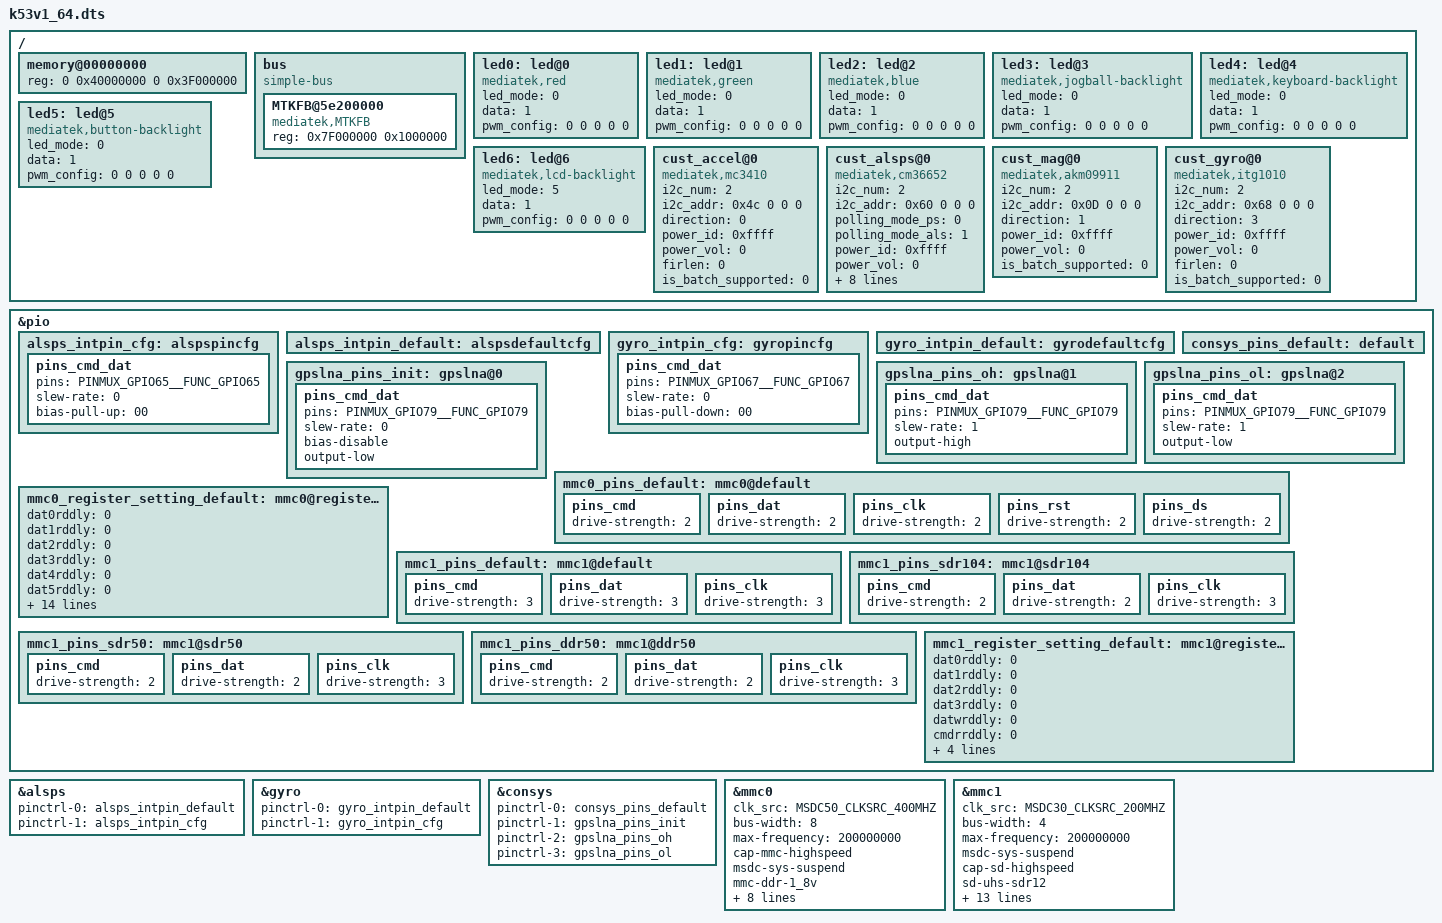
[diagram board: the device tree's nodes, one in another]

/dts-v1/;

#include "mt6753.dtsi"

/ {
	memory@00000000 {
		device_type = "memory";
		reg = <0 0x40000000 0 0x3F000000>;
	};

	bus {
		compatible = "simple-bus";
		#address-cells = <1>;
		#size-cells = <1>;
		ranges = <0 0 0 0xffffffff>;

		MTKFB@5e200000 {
			compatible = "mediatek,MTKFB";
			reg = <0x7F000000 0x1000000>;
		};
	};
	led0:led@0 {
		compatible = "mediatek,red";
		led_mode = <0>;
		data = <1>;
		pwm_config = <0 0 0 0 0>;
	};
	led1:led@1 {
		compatible = "mediatek,green";
		led_mode = <0>;
		data = <1>;
		pwm_config = <0 0 0 0 0>;
	};
	led2:led@2 {
		compatible = "mediatek,blue";
		led_mode = <0>;
		data = <1>;
		pwm_config = <0 0 0 0 0>;
	};
	led3:led@3 {
		compatible = "mediatek,jogball-backlight";
		led_mode = <0>;
		data = <1>;
		pwm_config = <0 0 0 0 0>;
	};
	led4:led@4 {
		compatible = "mediatek,keyboard-backlight";
		led_mode = <0>;
		data = <1>;
		pwm_config = <0 0 0 0 0>;
	};
	led5:led@5 {
		compatible = "mediatek,button-backlight";
		led_mode = <0>;
		data = <1>;
		pwm_config = <0 0 0 0 0>;
	};
	led6:led@6 {
		compatible = "mediatek,lcd-backlight";
		led_mode = <5>;
		data = <1>;
		pwm_config = <0 0 0 0 0>;
	};
 /* sensor standardization */
		cust_accel@0 {
		compatible = "mediatek,mc3410";
		i2c_num	= <2>;
		i2c_addr = <0x4c 0 0 0>;
		direction = <0>;
		power_id = <0xffff>;
		power_vol = <0>;
		firlen = <0>;
		is_batch_supported = <0>;
		};

		cust_alsps@0 {
		compatible = "mediatek,cm36652";
		i2c_num	= <2>;
		i2c_addr = <0x60 0 0 0>;
		polling_mode_ps = <0>;
		polling_mode_als = <1>;
		power_id = <0xffff>;
		power_vol = <0>;
		als_level = <0 213 711 1143 2630 6803 6909 10736 19968 24783 29231 42000 51141 51141 51141>;
		als_value = <0 135 303 501 1005 2005 3209 5002 8006 10010 12000 16010 20000 20000 20000 20000>;
		ps_threshold_high		=  <32>;
		ps_threshold_low		=  <22>;
		is_batch_supported_ps	= <0>;
		is_batch_supported_als	= <0>;
		};

		cust_mag@0 {
		compatible				= "mediatek,akm09911";
		i2c_num					= <2>;
		i2c_addr				= <0x0D 0 0 0>;
		direction				= <1>;
		power_id				= <0xffff>;
		power_vol				= <0>;
		is_batch_supported			= <0>;
		};

		cust_gyro@0 {
		compatible				= "mediatek,itg1010";
		i2c_num					= <2>;
		i2c_addr				= <0x68 0 0 0>;
		direction				= <3>;
		power_id				= <0xffff>;
		power_vol				= <0>;
		firlen					= <0>;
		is_batch_supported			= <0>;
		};
};
/* sensor gpio standization */
&pio {
	alsps_intpin_cfg: alspspincfg {

	    pins_cmd_dat {
			pins = <PINMUX_GPIO65__FUNC_GPIO65>;
			slew-rate = <0>;
			bias-pull-up = <00>;
		};
	};

	alsps_intpin_default: alspsdefaultcfg {

	};

	gyro_intpin_cfg: gyropincfg {

	    pins_cmd_dat {
			pins = <PINMUX_GPIO67__FUNC_GPIO67>;
			slew-rate = <0>;
			bias-pull-down = <00>;
		};
	};

	gyro_intpin_default: gyrodefaultcfg {

	};
};
&alsps {
	pinctrl-names = "pin_default", "pin_cfg";
	pinctrl-0 = <&alsps_intpin_default>;
	pinctrl-1 = <&alsps_intpin_cfg>;
	status = "okay";

};

&gyro {
	pinctrl-names = "pin_default", "pin_cfg";
	pinctrl-0 = <&gyro_intpin_default>;
	pinctrl-1 = <&gyro_intpin_cfg>;
	status = "okay";

};
/* sensor end */

/* CONSYS GPIO standardization */
&pio {
	consys_pins_default: default {

	};

	gpslna_pins_init: gpslna@0 {

	    pins_cmd_dat {
			pins = <PINMUX_GPIO79__FUNC_GPIO79>;
			slew-rate = <0>;
			bias-disable;
			output-low;
		};
	};

	gpslna_pins_oh: gpslna@1 {

	    pins_cmd_dat {
			pins = <PINMUX_GPIO79__FUNC_GPIO79>;
			slew-rate = <1>;
			output-high;
		};
	};

	gpslna_pins_ol: gpslna@2 {

	    pins_cmd_dat {
			pins = <PINMUX_GPIO79__FUNC_GPIO79>;
			slew-rate = <1>;
			output-low;
		};
	};

};

&consys {
	pinctrl-names = "default", "gps_lna_state_init", "gps_lna_state_oh", "gps_lna_state_ol";
	pinctrl-0 = <&consys_pins_default>;
	pinctrl-1 = <&gpslna_pins_init>;
	pinctrl-2 = <&gpslna_pins_oh>;
	pinctrl-3 = <&gpslna_pins_ol>;
	status = "okay";

};
/* CONSYS end */
/* mmc start */
&mmc0 {
		clk_src = /bits/ 8 <MSDC50_CLKSRC_400MHZ>;
		bus-width = <8>;
		max-frequency = <200000000>;
		cap-mmc-highspeed;
		msdc-sys-suspend;
		mmc-ddr-1_8v;
		mmc-hs200-1_8v;
		mmc-hs400-1_8v;
		non-removable;
		pinctl = <&mmc0_pins_default>;
		register_setting = <&mmc0_register_setting_default>;
		host_function = /bits/ 8 <MSDC_EMMC>;
		bootable;
		status = "okay";
};

&mmc1 {
		clk_src = /bits/ 8 <MSDC30_CLKSRC_200MHZ>;
		bus-width = <4>;
		max-frequency = <200000000>;
		msdc-sys-suspend;
		cap-sd-highspeed;
		sd-uhs-sdr12;
		sd-uhs-sdr25;
		sd-uhs-sdr50;
		sd-uhs-sdr104;
		sd-uhs-ddr50;
		pinctl = <&mmc1_pins_default>;
		pinctl_sdr104 = <&mmc1_pins_sdr104>;
		pinctl_sdr50 = <&mmc1_pins_sdr50>;
		pinctl_ddr50 = <&mmc1_pins_ddr50>;
		register_setting = <&mmc1_register_setting_default>;
		host_function = /bits/ 8 <MSDC_SD>;
		cd_level = /bits/ 8 <MSDC_CD_LOW>;
		cd-gpios = <&pio 5 0>;
		status = "okay";
};

&pio {
	mmc0_pins_default: mmc0@default {
			pins_cmd {
				drive-strength = /bits/ 8 <2>;
			};
			pins_dat {
				drive-strength = /bits/ 8 <2>;
			};
			pins_clk {
				drive-strength = /bits/ 8 <2>;
			};
			pins_rst {
				drive-strength = /bits/ 8 <2>;
			};
			pins_ds {
				drive-strength = /bits/ 8 <2>;
			};
	};

	mmc0_register_setting_default: mmc0@register_default {
		dat0rddly      = /bits/ 8 <0>;
		dat1rddly      = /bits/ 8 <0>;
		dat2rddly      = /bits/ 8 <0>;
		dat3rddly      = /bits/ 8 <0>;
		dat4rddly      = /bits/ 8 <0>;
		dat5rddly      = /bits/ 8 <0>;
		dat6rddly      = /bits/ 8 <0>;
		dat7rddly      = /bits/ 8 <0>;
		datwrddly      = /bits/ 8 <0>;
		cmdrrddly      = /bits/ 8 <0>;
		cmdrddly       = /bits/ 8 <0>;
		cmd_edge = /bits/ 8 <MSDC_SMPL_FALLING>;
		rdata_edge = /bits/ 8 <MSDC_SMPL_FALLING>;
		wdata_edge = /bits/ 8 <MSDC_SMPL_FALLING>;

		ett-hs200-cells = <12>;
		ett-hs200-default = <OFFSET_MSDC_PATCH_BIT0	MSDC_PB0_INT_DAT_LATCH_CK_SEL 0x0
			OFFSET_MSDC_PATCH_BIT0	MSDC_PB0_CKGEN_MSDC_DLY_SEL   0x0
			OFFSET_MSDC_PATCH_BIT1	MSDC_PB1_CMD_RSP_TA_CNTR      0x1
			OFFSET_MSDC_IOCON		MSDC_IOCON_RSPL               0x0
			OFFSET_MSDC_PAD_TUNE0	MSDC_PAD_TUNE0_CMDRDLY        0x7
			OFFSET_MSDC_PAD_TUNE0	MSDC_PAD_TUNE0_CMDRRDLY       0xb
			OFFSET_MSDC_PATCH_BIT1		MSDC_PB1_WRDAT_CRCS_TA_CNTR   0x1
			OFFSET_MSDC_PAD_TUNE0	MSDC_PAD_TUNE0_DATWRDLY       0xb
			OFFSET_MSDC_IOCON			MSDC_IOCON_W_D0SPL            0x0
			OFFSET_MSDC_DAT_RDDLY0		MSDC_DAT_RDDLY0_D0            0x7
			OFFSET_MSDC_PAD_TUNE0	MSDC_PAD_TUNE0_DATRRDLY       0x9
			OFFSET_MSDC_IOCON		MSDC_IOCON_R_D_SMPL           0x0>;

		ett-hs400-cells = <8>;
		ett-hs400-default = <OFFSET_MSDC_PATCH_BIT0	MSDC_PB0_INT_DAT_LATCH_CK_SEL	0x0
			OFFSET_MSDC_PATCH_BIT0		MSDC_PB0_CKGEN_MSDC_DLY_SEL		0x0
			OFFSET_EMMC50_PAD_DS_TUNE	MSDC_EMMC50_PAD_DS_TUNE_DLY1	0x2
			OFFSET_EMMC50_PAD_DS_TUNE	MSDC_EMMC50_PAD_DS_TUNE_DLY3	0x10
			OFFSET_MSDC_PATCH_BIT1			MSDC_PB1_CMD_RSP_TA_CNTR	0x1
			OFFSET_MSDC_IOCON		MSDC_IOCON_RSPL				0x0
			OFFSET_MSDC_PAD_TUNE0			MSDC_PAD_TUNE0_CMDRDLY		0x6
			OFFSET_MSDC_PAD_TUNE0		MSDC_PAD_TUNE0_CMDRRDLY		0x6>;
	};

	mmc1_pins_default: mmc1@default {
			pins_cmd {
				drive-strength = /bits/ 8 <3>;
			};
			pins_dat {
				drive-strength = /bits/ 8 <3>;
			};
			pins_clk {
				drive-strength = /bits/ 8 <3>;
			};
	};

	mmc1_pins_sdr104: mmc1@sdr104 {
			pins_cmd {
				drive-strength = /bits/ 8 <2>;
			};
			pins_dat {
				drive-strength = /bits/ 8 <2>;
			};
			pins_clk {
				drive-strength = /bits/ 8 <3>;
			};
	};

	mmc1_pins_sdr50: mmc1@sdr50 {
			pins_cmd {
				drive-strength = /bits/ 8 <2>;
			};
			pins_dat {
				drive-strength = /bits/ 8 <2>;
			};
			pins_clk {
				drive-strength = /bits/ 8 <3>;
			};
	};

	mmc1_pins_ddr50: mmc1@ddr50 {
			pins_cmd {
				drive-strength = /bits/ 8 <2>;
			};
			pins_dat {
				drive-strength = /bits/ 8 <2>;
			};
			pins_clk {
				drive-strength = /bits/ 8 <3>;
			};
	};

	mmc1_register_setting_default: mmc1@register_default {
				dat0rddly      = /bits/ 8 <0>;
				dat1rddly      = /bits/ 8 <0>;
				dat2rddly      = /bits/ 8 <0>;
				dat3rddly      = /bits/ 8 <0>;
				datwrddly      = /bits/ 8 <0>;
				cmdrrddly      = /bits/ 8 <0>;
				cmdrddly       = /bits/ 8 <0>;
				cmd_edge = /bits/ 8 <MSDC_SMPL_FALLING>;
				rdata_edge = /bits/ 8 <MSDC_SMPL_FALLING>;
				wdata_edge = /bits/ 8 <MSDC_SMPL_FALLING>;
	};
};
/* mmc end */

